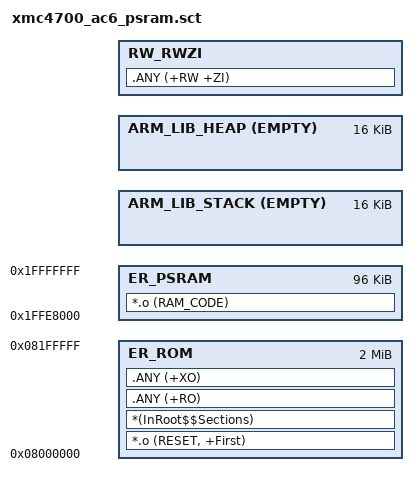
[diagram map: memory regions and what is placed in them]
#! armclang -E --target=arm-arm-none-eabi -mcpu=cortex-m4 -xc
/*
;-------- <<< Use Configuration Wizard in Context Menu >>> -------------------
*/

/*--------------------- Stack / Heap Configuration ---------------------------
; <h> Stack / Heap Configuration
;   <o0> Stack Size (in Bytes) <0x0-0xFFFFFFFF:8>
;   <o1> Heap Size (in Bytes) <0x0-0xFFFFFFFF:8>
;   <o2> gap before heap base (in Bytes) <0x0-0xFFFFFFFF:8>
;   <o3> gap between heap top and stack base (in Bytes) <0x0-0xFFFFFFFF:8>
;   <o4> gap between stack top and rw_zi base (in Bytes) <0x0-0xFFFFFFFF:8>
;   <o5> no init size (in Bytes) <0x0-0xFFFFFFFF:8>
; </h>
 *----------------------------------------------------------------------------*/
#define __STACK_SIZE		0x00004000
#define __HEAP_SIZE			0x00004000
#define	__GAP_INIT	0x100
#define __GAP_HEAP_TOP_STACK_BASE	0x100
#define __GAP_STACK_TOP_RW_BASE		0x100
#define __NO_INIT_SIZE         0x40

#define __ROM_BASE     0x08000000
;#define __ROM_BASE     0x0C000000
#define __ROM_SIZE     0x00200000

; PSRAM is used for possible RAM code section
#define __PSRAM_BASE   0x1FFE8000
#define __PSRAM_SIZE   0x00018000

; DSRAM1 and DSRAM2 is combined
#define __DSRAM_1_2_BASE  0x20000000
#define __DSRAM_1_2_SIZE  0x00040000

#define __RO_BASE         __ROM_BASE
#define __RO_SIZE         __ROM_SIZE

; Low	-> High
;|	Initial Gap	|	Heap	|	heap_stack gap	|	Stack	|	stack_rwzi gap	|	RW_ZI region	|	No_Init region	|

#define __HEAP_BASE			(AlignExpr(__DSRAM_1_2_BASE + __GAP_INIT, 8))
#define __HEAP_TOP			(AlignExpr(__HEAP_BASE + __HEAP_SIZE, 8))
#define __STACK_TOP			(AlignExpr(__HEAP_TOP + __GAP_HEAP_TOP_STACK_BASE + __STACK_SIZE, 8))
#define __RWZI_BASE			(AlignExpr(__GAP_STACK_TOP_RW_BASE + __STACK_TOP, 8))

#define __RWZI_SIZE			(AlignExpr(__DSRAM_1_2_SIZE - __GAP_INIT - __HEAP_SIZE - __GAP_HEAP_TOP_STACK_BASE - __STACK_SIZE - __GAP_STACK_TOP_RW_BASE - __NO_INIT_SIZE, 8))

LR_ROM __RO_BASE __RO_SIZE  {
  ER_ROM __RO_BASE __RO_SIZE  {
   *.o (RESET, +First)
   *(InRoot$$Sections)
   .ANY (+RO)
   .ANY (+XO)
  }

  ER_PSRAM __PSRAM_BASE __PSRAM_SIZE {
    *.o (RAM_CODE)                                ; Matches explicit section name from attributes
  }
  
  ARM_LIB_STACK __STACK_TOP EMPTY -__STACK_SIZE {
  }

  ARM_LIB_HEAP  __HEAP_BASE EMPTY  __HEAP_SIZE {
  }

  RW_RWZI __RWZI_BASE (__RWZI_SIZE)  {
   .ANY (+RW +ZI)
  }
}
